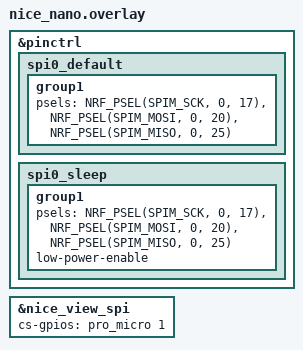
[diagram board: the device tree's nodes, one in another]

/* Override nice_view_adapter SPI pin assignments:
 * Your board has D2 and D3 swapped physically.
 *
 * nice!nano defaults (reference):
 *   SCK  = P0.20 (D3)
 *   MOSI = P0.17 (D2)
 *
 * Your wiring:
 *   SCK - blue wire - physically on D2 = P0.17
 *   MOSI - brown wire - physically on D3 = P0.20
 */


/* nice_view MOSI/SCK swapped fix (D2 <-> D3) for hardware wiring mistake.
 * Default: SCK=P0.20 (D3), MOSI=P0.17 (D2)
 * Swapped: SCK=P0.17 (D2), MOSI=P0.20 (D3)
 */
 
&pinctrl {
    /delete-node/ spi0_default;
    /delete-node/ spi0_sleep;

    spi0_default: spi0_default {
        group1 {
            psels =
                <NRF_PSEL(SPIM_SCK,  0, 17)>,
                <NRF_PSEL(SPIM_MOSI, 0, 20)>,
                <NRF_PSEL(SPIM_MISO, 0, 25)>;
        };
    };

    spi0_sleep: spi0_sleep {
        group1 {
            psels =
                <NRF_PSEL(SPIM_SCK,  0, 17)>,
                <NRF_PSEL(SPIM_MOSI, 0, 20)>,
                <NRF_PSEL(SPIM_MISO, 0, 25)>;
            low-power-enable;
        };
    };
};

/* Keep CS the same as your working sister board unless you *know* you wired it differently. */
&nice_view_spi {
    cs-gpios = <&pro_micro 1 GPIO_ACTIVE_HIGH>;
};
